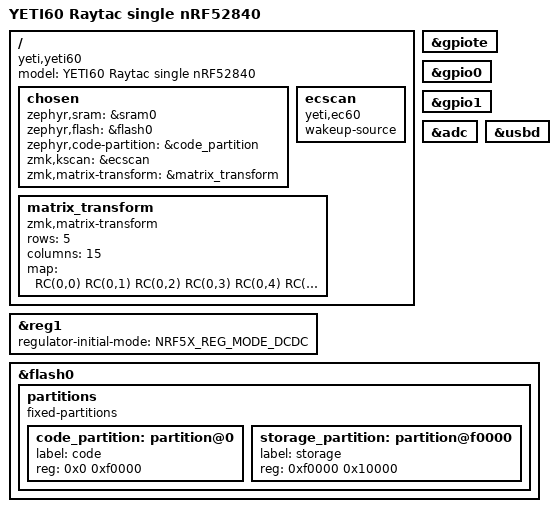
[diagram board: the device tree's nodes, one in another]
/dts-v1/;
#include <nordic/nrf52840_qiaa.dtsi>
#include <dt-bindings/zmk/matrix_transform.h>
/ {
    model = "YETI60 Raytac single nRF52840";
    compatible = "yeti,yeti60";
    chosen {
        zephyr,sram = &sram0;
        zephyr,flash = &flash0;
        zephyr,code-partition = &code_partition;
        zmk,kscan = &ecscan;
        zmk,matrix-transform = &matrix_transform;
    };
    ecscan: ecscan { compatible = "yeti,ec60"; wakeup-source; };
    matrix_transform: matrix_transform {
        compatible = "zmk,matrix-transform";
        rows = <5>; columns = <15>;
        map = <
            RC(0,0) RC(0,1) RC(0,2) RC(0,3) RC(0,4) RC(0,5) RC(0,6) RC(0,7) RC(0,8) RC(0,9) RC(0,10) RC(0,11) RC(0,12) RC(0,13) RC(0,14) RC(1,0) RC(1,1) RC(1,2) RC(1,3) RC(1,4) RC(1,5) RC(1,6) RC(1,7) RC(1,8) RC(1,9) RC(1,10) RC(1,11) RC(1,12) RC(1,13) RC(2,0) RC(2,1) RC(2,2) RC(2,3) RC(2,4) RC(2,5) RC(2,6) RC(2,7) RC(2,8) RC(2,9) RC(2,10) RC(2,11) RC(2,13) RC(3,0) RC(3,2) RC(3,3) RC(3,4) RC(3,5) RC(3,6) RC(3,7) RC(3,8) RC(3,9) RC(3,10) RC(3,11) RC(3,13) RC(3,14) RC(4,1) RC(4,2) RC(4,6) RC(4,9) RC(4,10)
        >;
    };
};
&gpiote { status = "okay"; };
&gpio0 { status = "okay"; };
&gpio1 { status = "okay"; };
/* MDBT50Q-1MV2 integrates the REG1 radio-rail inductor. REG0 remains LDO
 * because the board does not populate the external DCCH inductor. */
&reg1 {
    regulator-initial-mode = <NRF5X_REG_MODE_DCDC>;
};
&adc { status = "okay"; };
&usbd { status = "okay"; };
&flash0 {
    partitions {
        compatible = "fixed-partitions";
        #address-cells = <1>; #size-cells = <1>;
        code_partition: partition@0 { label = "code"; reg = <0x0 0xf0000>; };
        storage_partition: partition@f0000 { label = "storage"; reg = <0xf0000 0x10000>; };
    };
};
